# STC32G144K246 register map
Vendor: STC; File version: 2.0
Registers are 8-bit, read-write, no defined reset value unless marked. A register's access mark holds for its fields unless they carry their own. Offsets are from the block's base; [hi:lo] are bit positions.

## I2S2 — I2S2 音频接口
Base 0x007EFD90
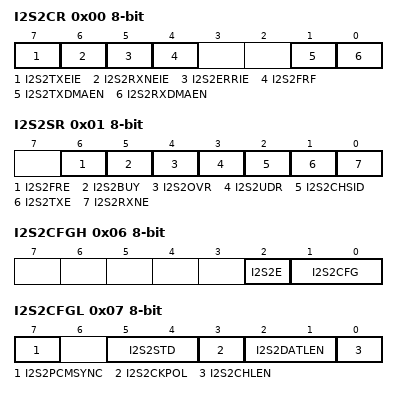
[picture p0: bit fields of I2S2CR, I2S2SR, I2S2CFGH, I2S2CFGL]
0x00 I2S2CR ro — I2S2控制寄存器
  [7] I2S2TXEIE — I2S2发送缓冲区空中断允许位。
    0=禁止I2S2 发送缓冲区空中断; 1=允许I2S2 发送缓冲区空中断
  [6] I2S2RXNEIE — I2S2接收缓冲区非空中断允许位。
    0=禁止I2S2 接收缓冲区非空中断; 1=允许I2S2 接收缓冲区非空中断
  [5] I2S2ERRIE — I2S2错误中断允许位。
    0=禁止I2S2 错误中断; 1=允许I2S2 错误中断
  [4] I2S2FRF — 帧格式（n=1/2）
    0=Motorola 格式; 1=TI 格式
  [1] I2S2TXDMAEN — 发送DMA控制（n=1/2）
    0=禁止发送DMA; 1=使能发送DMA
  [0] I2S2RXDMAEN — 接收DMA控制（n=1/2）
    0=禁止接收DMA; 1=使能接收DMA
0x01 I2S2SR ro — I2S2状态寄存器
  [6] I2S2FRE — 帧格式错误（n=1/2）
  [5] I2S2BUY — I2Sn忙状态。（n=1/2）（正在通讯中或者发送缓冲区非空）
  [4] I2S2OVR — 发生上溢（n=1/2）
  [3] I2S2UDR — 发生下溢（n=1/2）
  [2] I2S2CHSID — 通道选择标志（n=1/2）
    0=左通道正在发送或接收数据; 1=右通道正在发送或接收数据
  [1] I2S2TXE — I2S2发送缓冲区空中断中断请求标志。不需要软件清零。
  [0] I2S2RXNE — I2S2接收缓冲区非空中断请求标志。不需要软件清零。
0x06 I2S2CFGH — I2S2配置寄存器高字节
  [2] I2S2E — I2Sn模块控制（n=1/2）
    0=禁止I2S 功能; 1=使能I2S 功能
  [1:0] I2S2CFG — I2Sn模式配置（n=1/2）
    0=从机发送模式; 1=从机接收模式; 2=主机发送模式; 3=主机接收模式
0x07 I2S2CFGL — I2S2配置寄存器低字节
  [7] I2S2PCMSYNC — PCM帧同步（n=1/2）
    0=短帧同步; 1=长帧同步
  [5:4] I2S2STD — I2S标准选择（n=1/2）
    0=I2S 飞利浦标准; 1=MSB 左对齐标准; 2=LSB 右对齐标准; 3=PCM 标准
  [3] I2S2CKPOL — 稳态时钟极性（n=1/2）
    0=I2Sn 时钟稳定状态为低电平; 1=I2Sn 时钟稳定状态为高电平
  [2:1] I2S2DATLEN — 数据长度（n=1/2）
    0=16 位; 1=24 位; 2=32 位; 3=保留
  [0] I2S2CHLEN — 通道长度（每个音频通道的位数）（n=1/2）
    0=16 位; 1=32 位
0x14 I2S2MD ro
0x15 I2S2MCKDIV — I2S2时钟分频寄存器
  [7:0] I2S2MCKDIV — I2Sn 主时钟分频系数。（n=1/2） I2S 主时钟MCLK = 256*FS = I2S 时钟 / I2SnCLKDIV， 由此可计算出：I2SnCLKDIV = I2S 时钟 / (256*FS)。 当I2SnCLKDIV 为0 时，I2SnCLKDIV 仍默认为1。
0x105 I2S2_CLKDIV — I2S2时钟预分配寄存器
  [7:0] I2S2_CLKDIV — I2Sn 时钟分频系数。(n=1,2)

## TFPU — 浮点三角运算单元时钟；运算状态由专用指令访问
Base 0x007EFE93
0x00 TFPU_CLKDIV — TFPU时钟预分配寄存器
  [7:0] TFPU_CLKDIV — TFPU 时钟分频系数。

## DSP32 — DSP32 运算状态；不写入运算指令口
Base 0x10000086
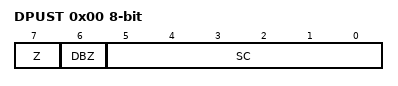
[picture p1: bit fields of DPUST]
0x00 DPUST ro — DSP32状态寄存器
  [7] Z — 零状态。
    0=计算结果不为0; 1=计算结果为0
  [6] DBZ — 除数为0状态
    0=除数不为0; 1=除数为0
  [5:0] SC — 规格化时移动的位数。

## CRC — 硬件 CRC16/32 控制及结果
Base 0x007EFB30
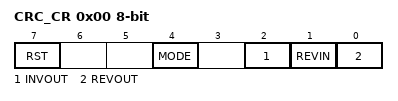
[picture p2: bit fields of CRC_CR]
0x00 CRC_CR ro — CRC控制寄存器
  [7] RST — 复位CRC 模块。软件向此位写1 触发复位CRC 模块，复位完成后，硬件自动将此位清零。
  [4] MODE — 选择CRC 模式
    0=CRC16，适用于MODEBUS 协议; 1=CRC32，适用于IEEE802.3 标准以太网协议
  [2] INVOUT — 计算结果取反控制
    0=结果不取反; 1=结果取反（计算结果与FFFF 或FFFFFFFF 异或）
  [1] REVIN — CRC 输入数据反转控制（数据的高位和低位交换，即bit0 和bit7 交换，bit1 和bit6 交换，…）
    0=输入数据不反转。写入CRC_DIN 的数据直接参与CRC 运算; 1=数据数据反转。写入CRC_DIN 的数据先反转，再参与CRC 运算
  [0] REVOUT — CRC 的输出结果反转控制
    0=结果不反转。内部计算的CRC 结果直接输出到CRC16_DOH 和CRC16_DOL; 1=结果反转。内部计算的CRC 结果先反转，再输出到CRC16_DOH 和CRC16_DOL
0x02 CRC_DO0 ro — 32位CRC结果最高字节
  [7:0] DOUT_32 — 32 位CRC 的计算结果
0x03 CRC_DO1 ro — 32位CRC结果高字节
  [7:0] DOUT_32 — 32 位CRC 的计算结果
0x04 CRC_DO2 ro — 32位CRC结果低字节
  [7:0] DOUT_32 — 32 位CRC 的计算结果
0x05 CRC_DO3 ro — 32位CRC结果最字节
  [7:0] DOUT_32 — 32 位CRC 的计算结果

## CAN_Interrupts — CAN-FD 公共中断控制
Base 0x100000F1
0x00 CANICR ro

## CAN1 — CAN-FD1 总线活动、接收队列、错误状态和计数
Base 0x007EF4A0
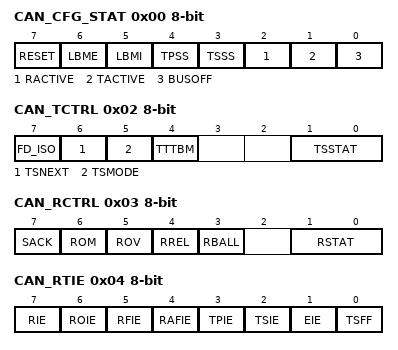
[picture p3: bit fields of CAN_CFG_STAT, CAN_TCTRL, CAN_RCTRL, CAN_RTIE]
0x00 CAN_CFG_STAT ro — CAN配置状态寄存器
  [7] RESET — 复位请求控制位
    0=不请求局部复位; 1=请求局部复位
  [6] LBME — 外部回环模式使能位（通信中禁止设定此位）
    0=禁止外部回环模式; 1=使能外部回环模式
  [5] LBMI — 内部回环模式使能位（通信中禁止设定此位）
    0=禁止内部回环模式; 1=使能内部回环模式
  [4] TPSS — PTB 单次传输模式使能位
    0=禁止PTB 单次传输模式; 1=使能PTB 单次传输模式
  [3] TSSS — STB 单次传输模式使能位
    0=禁止STB 单次传输模式; 1=使能STB 单次传输模式
  [2] RACTIVE — 接收状态信号（只读）
    0=非接收状态; 1=正在接收中
  [1] TACTIVE — 发送状态信号（只读）
    0=非发送状态; 1=正在发送中
  [0] BUSOFF — 总线关闭状态
    0=总线处于有效状态; 1=总线处于关闭状态
0x02 CAN_TCTRL ro — CAN发送控制寄存器
  [7] FD_ISO — CAN-FD ISO 模式选择
    0=Bosch CAN-FD 模式; 1=11898-1:2015 CAN-FD 模式
  [6] TSNEXT — 下一个STB
    0=无动作; 1=当前的STB SLOT 已填充，指向下一个SLOT
  [5] TSMODE — 尚未自动匹配到此字段的独立说明；请查看下方章节说明。
  [4] TTTBM — TTCAN BUF 模式
    0=TSMODE 决定PTB 和STB; 1=通过TBPTR 和TTPTR 设定
  [1:0] TSSTAT — 尚未自动匹配到此字段的独立说明；请查看下方章节说明。
0x03 CAN_RCTRL ro — CAN接收控制寄存器
  [7] SACK — 自应答
    0=无应答; 1=LBME==1 时，使能自应答功能
  [6] ROM — 接收BUF 上溢模式设置
    0=最早接收的数据被覆盖; 1=新接收的数据不存储
  [5] ROV — 接收BUF 上溢标志位（只读）
    0=无上溢; 1=发生上溢，需通过写1 到RREL 位来清零ROV
  [4] RREL — 释放接收BUF
    0=不释放; 1=表示该接收BUF 已经被读取过，RBUF 寄存器指向下一个RB SLOT
  [3] RBALL — 接收BUF 数据存储所有的数据帧
    0=正常模式; 1=存储所有的数据包（包括有错误的数据）
  [1:0] RSTAT — 错误类型（只读）
    0=RBUF 空; 1=RBUF 非空且小于AFWL 的设定值; 2=RBUF 非空且大于等于AFWL 的设定值; 3=RBUF 满（上溢时保持此值）
0x04 CAN_RTIE ro — CAN中断使能寄存器
  [7] RIE — 接收中断控制位
    0=禁止; 1=使能
  [6] ROIE — 接收上溢中断控制位
    0=禁止; 1=使能
  [5] RFIE — 接收BUF 满中断控制位
    0=禁止; 1=使能
  [4] RAFIE — 接收BUF 将满中断控制位
    0=禁止; 1=使能
  [3] TPIE — PTB 发送中断控制位
    0=禁止; 1=使能
  [2] TSIE — STB 发送中断控制位
    0=禁止; 1=使能
  [1] EIE — 错误中断控制位
    0=禁止; 1=使能
  [0] TSFF — 发送BUF 满标志 TTEN==0 || TTTBM==0 时STB 满标志
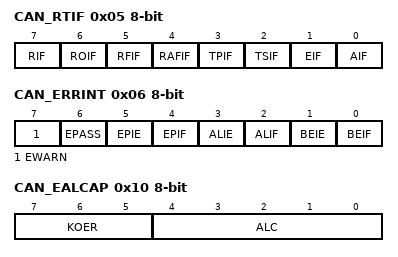
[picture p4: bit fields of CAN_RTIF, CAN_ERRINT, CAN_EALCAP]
0x05 CAN_RTIF ro — CAN中断状态寄存器
  [7] RIF — 接收中断标志位。需要软件写“1”清零
    0=未接收到数据帧; 1=接收到有效的数据帧或远程帧
  [6] ROIF — 接收上溢中断标志位。需要软件写“1”清零
    0=无RB 被覆盖; 1=至少有一个RB 被覆盖
  [5] RFIF — 接收BUF 满中断标志位。需要软件写“1”清零
    0=RB FIFO 未满; 1=RB FIFO 满
  [4] RAFIF — 接收BUF 将满中断标志位。需要软件写“1”清零
    0=被填充的RB SLOT 数目小于AFWL 设置的值; 1=被填充的RB SLOT 数目大于等于AFWL 设置的值
  [3] TPIF — PTB 发送中断标志位。需要软件写“1”清零
    0=没有PTB 发送完成; 1=请求的PTB 发送完成
  [2] TSIF — STB 发送中断标志位。需要软件写“1”清零
    0=没有STB 发送完成; 1=请求的STB 发送完成
  [1] EIF — 错误中断标志位。需要软件写“1”清零
    0=BUSOFF 位未发生变化，或者错误计数器的值与EWL 设置的值相对关系未发生变化; 1=BUSOFF 位发生变化，或者错误计数器的值与EWL 设置的值相对关系发生变化
  [0] AIF — 取消发送中断标志位。需要软件写“1”清零
    0=未取消发送数据; 1=通过TPA 和TSA 请求的发送消息被成功取消
0x06 CAN_ERRINT ro — CAN错误中断寄存器
  [7] EWARN — 错误计数器的值状态（只读）
    0=错误计数器（RECNT 或者TECNT）的值小于EWL 设置的值; 1=错误计数器（RECNT 或者TECNT）的值大于或等于EWL 设置的值
  [6] EPASS — 错误被动（只读）
    0=节点是主动错误节点; 1=节点是被动错误节点
  [5] EPIE — 错误被动中断控制位
    0=禁止; 1=使能
  [4] EPIF — 错误被动中断标志位。需要软件写“1”清零
    0=未发生错误主动到错误被动或者错误被动到错误主动的变化; 1=发生错误主动到错误被动或者错误被动到错误主动的变化
  [3] ALIE — 仲裁失败中断控制位
    0=禁止; 1=使能
  [2] ALIF — 仲裁失败中断标志位。需要软件写“1”清零
    0=仲裁成功; 1=仲裁失败
  [1] BEIE — 总线错误中断控制位
    0=禁止; 1=使能
  [0] BEIF — 总线错误中断标志位。需要软件写“1”清零
    0=无总线错误; 1=发生总线错误
0x10 CAN_EALCAP ro — CAN错误和仲裁丢失捕获
  [7:5] KOER — 错误类型（只读）
    0=无错误; 1=位错误; 2=形式错误; 3=填充错误; 4=应答错误; 5=CRC 错误; 6=其他错误; 7=保留
  [4:0] ALC — 仲裁失败位置捕获。仲裁失败时ALC 记录一帧数据中仲裁失败时的位置。（只读）
0x12 CAN_RECNT ro — CAN接收错误计数器
  [7:0] RECNT — 接收错误计数器。计数器不会上溢，最大值为255。（只读）
0x13 CAN_TECNT ro — CAN发送错误计数器
  [7:0] TECNT — 尚未自动匹配到此字段的独立说明；请查看下方章节说明。

## CAN2 — CAN-FD2 总线活动、接收队列、错误状态和计数
Base 0x007EF3A0
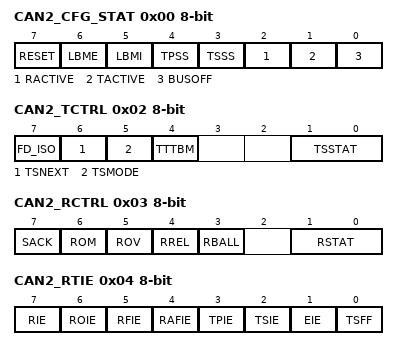
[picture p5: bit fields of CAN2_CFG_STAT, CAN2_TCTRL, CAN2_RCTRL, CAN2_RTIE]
0x00 CAN2_CFG_STAT ro — CAN2配置状态寄存器
  [7] RESET — 复位请求控制位
    0=不请求局部复位; 1=请求局部复位
  [6] LBME — 外部回环模式使能位（通信中禁止设定此位）
    0=禁止外部回环模式; 1=使能外部回环模式
  [5] LBMI — 内部回环模式使能位（通信中禁止设定此位）
    0=禁止内部回环模式; 1=使能内部回环模式
  [4] TPSS — PTB 单次传输模式使能位
    0=禁止PTB 单次传输模式; 1=使能PTB 单次传输模式
  [3] TSSS — STB 单次传输模式使能位
    0=禁止STB 单次传输模式; 1=使能STB 单次传输模式
  [2] RACTIVE — 接收状态信号（只读）
    0=非接收状态; 1=正在接收中
  [1] TACTIVE — 发送状态信号（只读）
    0=非发送状态; 1=正在发送中
  [0] BUSOFF — 总线关闭状态
    0=总线处于有效状态; 1=总线处于关闭状态
0x02 CAN2_TCTRL ro — CAN2发送控制寄存器
  [7] FD_ISO — CAN-FD ISO 模式选择
    0=Bosch CAN-FD 模式; 1=11898-1:2015 CAN-FD 模式
  [6] TSNEXT — 下一个STB
    0=无动作; 1=当前的STB SLOT 已填充，指向下一个SLOT
  [5] TSMODE — 尚未自动匹配到此字段的独立说明；请查看下方章节说明。
  [4] TTTBM — TTCAN BUF 模式
    0=TSMODE 决定PTB 和STB; 1=通过TBPTR 和TTPTR 设定
  [1:0] TSSTAT — 尚未自动匹配到此字段的独立说明；请查看下方章节说明。
0x03 CAN2_RCTRL ro — CAN2接收控制寄存器
  [7] SACK — 自应答
    0=无应答; 1=LBME==1 时，使能自应答功能
  [6] ROM — 接收BUF 上溢模式设置
    0=最早接收的数据被覆盖; 1=新接收的数据不存储
  [5] ROV — 接收BUF 上溢标志位（只读）
    0=无上溢; 1=发生上溢，需通过写1 到RREL 位来清零ROV
  [4] RREL — 释放接收BUF
    0=不释放; 1=表示该接收BUF 已经被读取过，RBUF 寄存器指向下一个RB SLOT
  [3] RBALL — 接收BUF 数据存储所有的数据帧
    0=正常模式; 1=存储所有的数据包（包括有错误的数据）
  [1:0] RSTAT — 错误类型（只读）
    0=RBUF 空; 1=RBUF 非空且小于AFWL 的设定值; 2=RBUF 非空且大于等于AFWL 的设定值; 3=RBUF 满（上溢时保持此值）
0x04 CAN2_RTIE ro — CAN2中断使能寄存器
  [7] RIE — 接收中断控制位
    0=禁止; 1=使能
  [6] ROIE — 接收上溢中断控制位
    0=禁止; 1=使能
  [5] RFIE — 接收BUF 满中断控制位
    0=禁止; 1=使能
  [4] RAFIE — 接收BUF 将满中断控制位
    0=禁止; 1=使能
  [3] TPIE — PTB 发送中断控制位
    0=禁止; 1=使能
  [2] TSIE — STB 发送中断控制位
    0=禁止; 1=使能
  [1] EIE — 错误中断控制位
    0=禁止; 1=使能
  [0] TSFF — 发送BUF 满标志 TTEN==0 || TTTBM==0 时STB 满标志
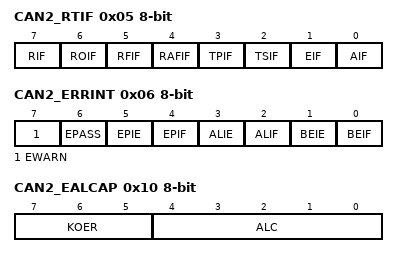
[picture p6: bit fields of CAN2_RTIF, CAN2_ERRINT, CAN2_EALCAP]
0x05 CAN2_RTIF ro — CAN2中断状态寄存器
  [7] RIF — 接收中断标志位。需要软件写“1”清零
    0=未接收到数据帧; 1=接收到有效的数据帧或远程帧
  [6] ROIF — 接收上溢中断标志位。需要软件写“1”清零
    0=无RB 被覆盖; 1=至少有一个RB 被覆盖
  [5] RFIF — 接收BUF 满中断标志位。需要软件写“1”清零
    0=RB FIFO 未满; 1=RB FIFO 满
  [4] RAFIF — 接收BUF 将满中断标志位。需要软件写“1”清零
    0=被填充的RB SLOT 数目小于AFWL 设置的值; 1=被填充的RB SLOT 数目大于等于AFWL 设置的值
  [3] TPIF — PTB 发送中断标志位。需要软件写“1”清零
    0=没有PTB 发送完成; 1=请求的PTB 发送完成
  [2] TSIF — STB 发送中断标志位。需要软件写“1”清零
    0=没有STB 发送完成; 1=请求的STB 发送完成
  [1] EIF — 错误中断标志位。需要软件写“1”清零
    0=BUSOFF 位未发生变化，或者错误计数器的值与EWL 设置的值相对关系未发生变化; 1=BUSOFF 位发生变化，或者错误计数器的值与EWL 设置的值相对关系发生变化
  [0] AIF — 取消发送中断标志位。需要软件写“1”清零
    0=未取消发送数据; 1=通过TPA 和TSA 请求的发送消息被成功取消
0x06 CAN2_ERRINT ro — CAN2错误中断寄存器
  [7] EWARN — 错误计数器的值状态（只读）
    0=错误计数器（RECNT 或者TECNT）的值小于EWL 设置的值; 1=错误计数器（RECNT 或者TECNT）的值大于或等于EWL 设置的值
  [6] EPASS — 错误被动（只读）
    0=节点是主动错误节点; 1=节点是被动错误节点
  [5] EPIE — 错误被动中断控制位
    0=禁止; 1=使能
  [4] EPIF — 错误被动中断标志位。需要软件写“1”清零
    0=未发生错误主动到错误被动或者错误被动到错误主动的变化; 1=发生错误主动到错误被动或者错误被动到错误主动的变化
  [3] ALIE — 仲裁失败中断控制位
    0=禁止; 1=使能
  [2] ALIF — 仲裁失败中断标志位。需要软件写“1”清零
    0=仲裁成功; 1=仲裁失败
  [1] BEIE — 总线错误中断控制位
    0=禁止; 1=使能
  [0] BEIF — 总线错误中断标志位。需要软件写“1”清零
    0=无总线错误; 1=发生总线错误
0x10 CAN2_EALCAP ro — CAN2错误和仲裁丢失捕获
  [7:5] KOER — 错误类型（只读）
    0=无错误; 1=位错误; 2=形式错误; 3=填充错误; 4=应答错误; 5=CRC 错误; 6=其他错误; 7=保留
  [4:0] ALC — 仲裁失败位置捕获。仲裁失败时ALC 记录一帧数据中仲裁失败时的位置。（只读）
0x12 CAN2_RECNT ro — CAN2接收错误计数器
  [7:0] RECNT — 接收错误计数器。计数器不会上溢，最大值为255。（只读）
0x13 CAN2_TECNT ro — CAN2发送错误计数器
  [7:0] TECNT — 尚未自动匹配到此字段的独立说明；请查看下方章节说明。
